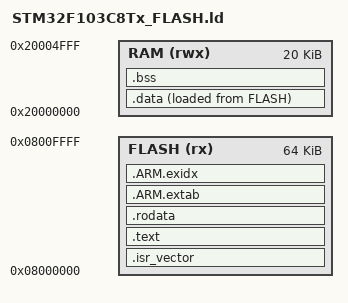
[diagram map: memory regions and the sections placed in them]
/**
 * STM32F103C8Tx 链接脚本
 * Flash: 64KB  RAM: 20KB
 */

ENTRY(Reset_Handler)

MEMORY
{
    FLASH (rx)  : ORIGIN = 0x08000000, LENGTH = 64K
    RAM   (rwx) : ORIGIN = 0x20000000, LENGTH = 20K
}

_estack = ORIGIN(RAM) + LENGTH(RAM);

/* 参数存储槽 (Flash 末尾两页, 每页 1KB) */
_param_slot0 = 0x0800F800;
_param_slot1 = 0x0800FA00;

SECTIONS
{
    .isr_vector :
    {
        . = ALIGN(4);
        KEEP(*(.isr_vector))
        . = ALIGN(4);
    } > FLASH

    .text :
    {
        . = ALIGN(4);
        *(.text)
        *(.text*)
        *(.glue_7)
        *(.glue_7t)
        *(.eh_frame)
        KEEP(*(.init))
        KEEP(*(.fini))
        . = ALIGN(4);
        _etext = .;
    } > FLASH

    .rodata :
    {
        . = ALIGN(4);
        *(.rodata)
        *(.rodata*)
        . = ALIGN(4);
    } > FLASH

    .ARM.extab :
    {
        . = ALIGN(4);
        *(.ARM.extab* .gnu.linkonce.armextab.*)
        . = ALIGN(4);
    } > FLASH

    .ARM.exidx :
    {
        . = ALIGN(4);
        __exidx_start = .;
        *(.ARM.exidx* .gnu.linkonce.armexidx.*)
        __exidx_end = .;
        . = ALIGN(4);
    } > FLASH

    _sidata = LOADADDR(.data);

    .data :
    {
        . = ALIGN(4);
        _sdata = .;
        *(.data)
        *(.data*)
        . = ALIGN(4);
        _edata = .;
    } > RAM AT> FLASH

    .bss :
    {
        . = ALIGN(4);
        _sbss = .;
        *(.bss)
        *(.bss*)
        *(COMMON)
        . = ALIGN(4);
        _ebss = .;
    } > RAM

    end = .;
}
